# CPPI_DMA register map
Vendor: Texas Instruments
Peripheral module from a debugger description file (folder am335x).
Registers are 32-bit, access per field, no defined reset value unless marked. A register's access mark holds for its fields unless they carry their own. Offsets are as the file gives them; lines under a group give offsets from that group; [hi:lo] are bit positions; {n}, {i} and the like mark numbered series; 'fields as' and 'values as' point back to an identical list; <NAME> marks a mode.

## CPPI_DMA
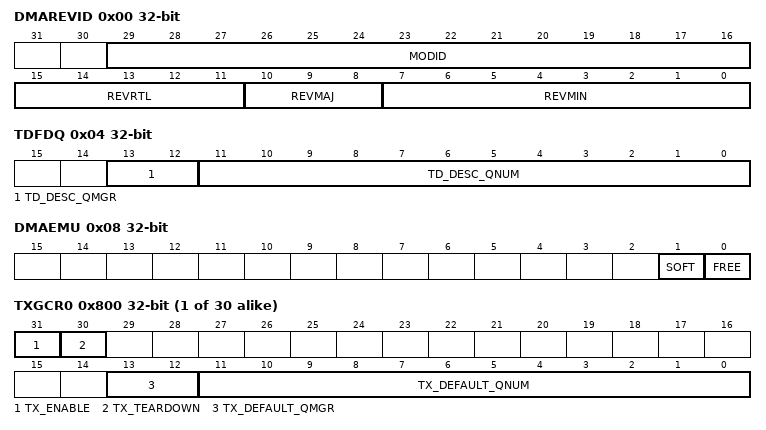
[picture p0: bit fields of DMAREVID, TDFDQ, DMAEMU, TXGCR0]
0x00 DMAREVID ro
  [29:16] MODID — Module ID field
  [15:11] REVRTL — RTL revision. Will vary depending on release.
  [10:8] REVMAJ — Major revision.
  [7:0] REVMIN — Minor revision. CPPI DMA Revision Register
0x04 TDFDQ rw
  [13:12] TD_DESC_QMGR — This field controls which of the 4 Queue Managers the DMA will access in order to allocate a channel teardown descriptor from the teardown descriptor queue.
  [11:0] TD_DESC_QNUM — This field controls which of the 2K queues in the indicated queue manager should be read in order to allocate channel teardown descriptors. CPPI DMA Teardown Free Descriptor Queue Control Register
0x08 DMAEMU rw
  [1] SOFT — Control for emulation pause request 1 = Does not force emu_pause_req low 0 = Forces emu_pause_req low
  [0] FREE — Enable for emulation suspend CPPI DMA Emulation Control Register
{0x800+0x20*i} TXGCR{i} (i=0..29)
  [31] TX_ENABLE rw — This field enables or disables the channel 0 = channel is disabled 1 = channel is enabled This field will be cleared after a channel teardown is complete.
  [30] TX_TEARDOWN rw — Setting this bit will request the channel to be torn down. This field will remain set after a channel teardown is complete.
  [13:12] TX_DEFAULT_QMGR wo — This field controls the default queue manager number that will be used to queue teardown descriptors back to the host.
  [11:0] TX_DEFAULT_QNUM wo — This field controls the default queue number within the selected queue manager onto which teardown descriptors will be queued back to the host. Table 98 -Tx Channel N Global Configuration Registers
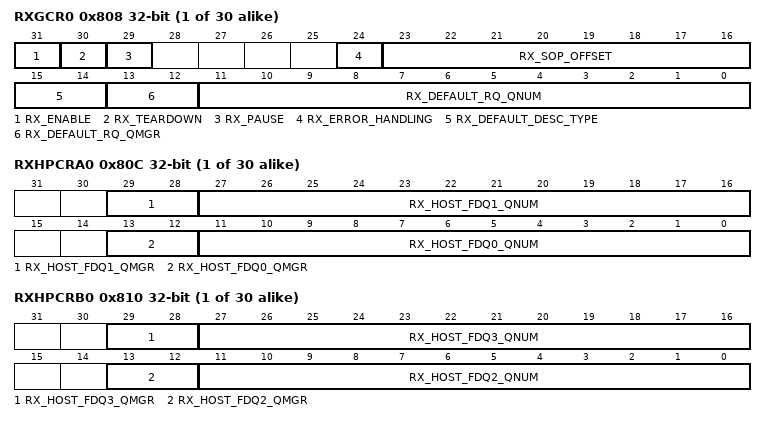
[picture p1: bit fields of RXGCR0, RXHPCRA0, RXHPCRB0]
{0x808+0x20*i} RXGCR{i} (i=0..29)
  [31] RX_ENABLE rw — This field enables or disables the channel 0 = channel is disabled 1 = channel is enabled This field will be cleared after a channel teardown is complete.
  [30] RX_TEARDOWN rw — This field indicates whether or not an Rx teardown operation is complete. This field should be cleared when a channel is initialized. This field will be set after a channel teardown is complete.
  [29] RX_PAUSE rw — Setting this bit causes the CPPI DMA to be suspended for rx channels. If a pause is being requested and the channel is not in a packet then drop the credit.
  [24] RX_ERROR_HANDLING wo — This bit controls the error handling mode for the channel and is only used when channel errors (i.e. descriptor or buffer starvation occurs): 0 = Starvation errors result in dropping packet and reclaiming any used descriptor or buffer resources back to the original queues/pools they were allocated to 1 = Starvation errors result in subsequent re-try of the descriptor allocation operation. In this mode, the DMA will return to the IDLE state without saving it's internal operational state back to the internal state RAM and without issuing an advance operation on the FIFO interface. This results in the DMA re-initiating the FIFO block transfer at a later time with the intention that additional free buffers and/or descriptors will have been added. Regardless of the value of this bit, the DMA will assert the cdma_rx_sof_overrun (for SOP) or cdma_rx_mof_overrun (for non-SOP) when
  [23:16] RX_SOP_OFFSET wo — This field specifies the number of bytes that are to be skipped in the SOP buffer before beginning to write the payload. This value must be less than the minimum size of a buffer in the system. Valid values are 0 - 255 bytes.
  [15:14] RX_DEFAULT_DESC_TYPE wo — This field indicates the default descriptor type to use: 0 = Reserved 1 = Host 2 = Reserved 3 = Reserved The actual descriptor type that will be used for reception can be overridden by information provided in the CPPI FIFO data block.
  [13:12] RX_DEFAULT_RQ_QMGR wo — This field indicates the default receive queue manager that this channel should use. The actual receive queue manager index can be overridden by information provided in the CPPI FIFO data block.
  [11:0] RX_DEFAULT_RQ_QNUM wo — This field indicates the default receive queue that this channel should use. The actual receive queue that will be used for reception can be overridden by information provided in the CPPI FIFO data block. Table 99 -Rx Channel N Global Configuration Registers
{0x80C+0x20*i} RXHPCRA{i} wo (i=0..29)
  [29:28] RX_HOST_FDQ1_QMGR — This field specifies which Buffer Manager should be used for the second Rx buffer in a host type packet.
  [27:16] RX_HOST_FDQ1_QNUM — This field specifies which Free Descriptor / Buffer Pool should be used for the 2nd Rx buffer in a host type packet
  [13:12] RX_HOST_FDQ0_QMGR — This field specifies which Buffer Manager should be used for the second Rx buffer in a host type packet.
  [11:0] RX_HOST_FDQ0_QNUM — This field specifies which Free Descriptor / Buffer Pool should be used for the 1st Rx buffer in a host type packet Table 100 -Rx Channel N Host Packet Configuration Registers A
{0x810+0x20*i} RXHPCRB{i} wo (i=0..29)
  [29:28] RX_HOST_FDQ3_QMGR — This field specifies which Manager should be used for the 4th or later Rx buffers in a host type packet
  [27:16] RX_HOST_FDQ3_QNUM — This field specifies which Free Descriptor Queue should be used for the 4th or later Rx buffers in a host type packet
  [13:12] RX_HOST_FDQ2_QMGR — This field specifies which Buffer Manager should be used for the 3rd Rx buffer in a host type packet
  [11:0] RX_HOST_FDQ2_QNUM — This field specifies which Free Descriptor / Buffer Pool should be used for the 3rd Rx buffer in a host type packet Table 101 -Rx Channel N Host Packet Configuration Registers B
